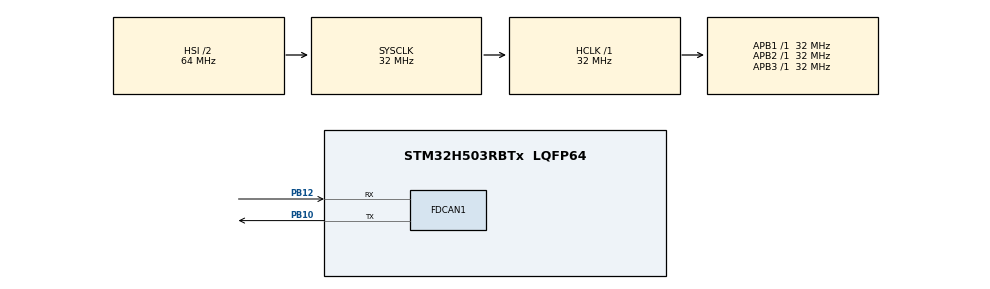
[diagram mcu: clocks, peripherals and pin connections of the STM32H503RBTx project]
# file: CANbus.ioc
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BOOTPATH.BootPathName=LEGACY
BOOTPATH.UserSelectedBootPath=LEGACY
FDCAN1.CalculateBaudRateNominal=500000
FDCAN1.CalculateTimeBitNominal=2000
FDCAN1.CalculateTimeQuantumNominal=200.0
FDCAN1.Mode=FDCAN_MODE_EXTERNAL_LOOPBACK
FDCAN1.NominalPrescaler=10
FDCAN1.NominalTimeSeg1=8
FDCAN1.NominalTimeSeg2=1
Mcu.Family=STM32H5
Mcu.Name=STM32H503RBTx
Mcu.Package=LQFP64
NVIC.FDCAN1_IT0_IRQn=true\:0\:0\:false\:false\:true\:true\:true\:true
NVIC.PriorityGroup=NVIC_PRIORITYGROUP_4
PB10.Mode=FDCAN_Activate
PB10.Signal=FDCAN1_TX
PB12.Mode=FDCAN_Activate
PB12.Signal=FDCAN1_RX
ProjectManager.HeapSize=0x200
ProjectManager.StackSize=0x400
ProjectManager.TargetToolchain=STM32CubeIDE
RCC.ADCFreq_Value=32000000
RCC.AHBFreq_Value=32000000
RCC.APB1Freq_Value=32000000
RCC.APB1TimFreq_Value=32000000
RCC.APB2Freq_Value=32000000
RCC.APB2TimFreq_Value=32000000
RCC.APB3Freq_Value=32000000
RCC.CSI_VALUE=4000000
RCC.CortexFreq_Value=32000000
RCC.EPOD_VALUE=4000000
RCC.FDCANClockSelection=RCC_FDCANCLKSOURCE_PLL1Q
RCC.HCLKFreq_Value=32000000
RCC.HSE_VALUE=25000000
RCC.HSI48_VALUE=48000000
RCC.HSI_VALUE=64000000
RCC.LSE_VALUE=32768
RCC.LSIRC_VALUE=32000
RCC.PLL1Q=4
RCC.PLLFRACN=0
RCC.PLLN=50
RCC.SYSCLKFreq_VALUE=32000000
RCC.USBFreq_Value=48000000
RCC.VCOOutputFreq_Value=200000000
VP_BOOTPATH_VS_BOOTPATH.Mode=BP_Activate
VP_CORTEX_M33_NS_VS_Hclk.Mode=Hclk_Mode
VP_CRC_VS_CRC.Mode=CRC_Activate
VP_ICACHE_VS_ICACHE.Mode=DirectMappedCache
VP_MEMORYMAP_VS_MEMORYMAP.Mode=CurAppReg
VP_PWR_VS_DBSignals.Mode=DisableDeadBatterySignals
VP_PWR_VS_LPOM.Mode=PowerOptimisation
VP_PWR_VS_SECSignals.Mode=Security/Privilege
board=custom

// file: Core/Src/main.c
/* USER CODE BEGIN Header */
/**
  ******************************************************************************
  * @file           : main.c
  * @brief          : Main program body
  ******************************************************************************
  * @attention
  *
  * Copyright (c) 2025 STMicroelectronics.
  * All rights reserved.
  *
  * This software is licensed under terms that can be found in the LICENSE file
  * in the root directory of this software component.
  * If no LICENSE file comes with this software, it is provided AS-IS.
  *
  ******************************************************************************
  */
/* USER CODE END Header */
#include "main.h"

CRC_HandleTypeDef hcrc;

FDCAN_HandleTypeDef hfdcan1;

/* USER CODE BEGIN PV */
FDCAN_TxHeaderTypeDef   TxHeader;
FDCAN_RxHeaderTypeDef   RxHeader;
uint8_t               TxData[8];
uint8_t               RxData[8];
int indx = 0;
/* USER CODE END PV */

void SystemClock_Config(void);
static void MX_GPIO_Init(void);
static void MX_FDCAN1_Init(void);
static void MX_ICACHE_Init(void);
static void MX_CRC_Init(void);

/* USER CODE BEGIN 0 */
void HAL_FDCAN_RxFifo0Callback(FDCAN_HandleTypeDef *hfdcan, uint32_t RxFifo0ITs)
{
	if((RxFifo0ITs & FDCAN_IT_RX_FIFO0_NEW_MESSAGE) != RESET)
	{
		/* Retreive Rx messages from RX FIFO0 */
		if (HAL_FDCAN_GetRxMessage(hfdcan, FDCAN_RX_FIFO0, &RxHeader, RxData) != HAL_OK)
		{
			/* Reception Error */
			Error_Handler();
		}
		if (HAL_FDCAN_ActivateNotification(hfdcan, FDCAN_IT_RX_FIFO0_NEW_MESSAGE, 0) != HAL_OK)
		{
			/* Notification Error */
			Error_Handler();
		}
	}
}
/* USER CODE END 0 */

int main(void)
{

  /* MCU Configuration--------------------------------------------------------*/

  /* Reset of all peripherals, Initializes the Flash interface and the Systick. */
  HAL_Init();

  /* Configure the system clock */
  SystemClock_Config();

  /* Initialize all configured peripherals */
  MX_GPIO_Init();
  MX_FDCAN1_Init();
  MX_ICACHE_Init();
  MX_CRC_Init();
  /* USER CODE BEGIN 2 */
  if(HAL_FDCAN_Start(&hfdcan1)!= HAL_OK)
  {
	Error_Handler();
  }
  if (HAL_FDCAN_ActivateNotification(&hfdcan1, FDCAN_IT_RX_FIFO0_NEW_MESSAGE, 0) != HAL_OK)
  {
	/* Notification Error */
	Error_Handler();
  }

  TxHeader.Identifier = 0x1;
  TxHeader.IdType = FDCAN_STANDARD_ID;
  TxHeader.TxFrameType = FDCAN_DATA_FRAME;
  TxHeader.DataLength = FDCAN_DLC_BYTES_8;
  TxHeader.ErrorStateIndicator = FDCAN_ESI_ACTIVE;
  TxHeader.BitRateSwitch = FDCAN_BRS_OFF;
  TxHeader.FDFormat = FDCAN_FD_CAN;
  TxHeader.TxEventFifoControl = FDCAN_NO_TX_EVENTS;
  TxHeader.MessageMarker = 0;

  for (int i=0; i<8; i++)
  {
	  TxData[i] = i;
  }

  if (HAL_FDCAN_AddMessageToTxFifoQ(&hfdcan1, &TxHeader, TxData)!= HAL_OK)
  {
	  Error_Handler();
  }
  /* USER CODE END 2 */

  /* Infinite loop */
  while (1)
  {

  }
}

void SystemClock_Config(void)
{
  RCC_OscInitTypeDef RCC_OscInitStruct = {0};
  RCC_ClkInitTypeDef RCC_ClkInitStruct = {0};

  /** Configure the main internal regulator output voltage
  */
  __HAL_PWR_VOLTAGESCALING_CONFIG(PWR_REGULATOR_VOLTAGE_SCALE3);

  while(!__HAL_PWR_GET_FLAG(PWR_FLAG_VOSRDY)) {}

  /** Initializes the RCC Oscillators according to the specified parameters
  * in the RCC_OscInitTypeDef structure.
  */
  RCC_OscInitStruct.OscillatorType = RCC_OSCILLATORTYPE_HSI|RCC_OSCILLATORTYPE_CSI;
  RCC_OscInitStruct.HSIState = RCC_HSI_ON;
  RCC_OscInitStruct.HSIDiv = RCC_HSI_DIV2;
  RCC_OscInitStruct.HSICalibrationValue = RCC_HSICALIBRATION_DEFAULT;
  RCC_OscInitStruct.CSIState = RCC_CSI_ON;
  RCC_OscInitStruct.CSICalibrationValue = RCC_CSICALIBRATION_DEFAULT;
  RCC_OscInitStruct.PLL.PLLState = RCC_PLL_ON;
  RCC_OscInitStruct.PLL.PLLSource = RCC_PLL1_SOURCE_CSI;
  RCC_OscInitStruct.PLL.PLLM = 1;
  RCC_OscInitStruct.PLL.PLLN = 50;
  RCC_OscInitStruct.PLL.PLLP = 2;
  RCC_OscInitStruct.PLL.PLLQ = 4;
  RCC_OscInitStruct.PLL.PLLR = 2;
  RCC_OscInitStruct.PLL.PLLRGE = RCC_PLL1_VCIRANGE_2;
  RCC_OscInitStruct.PLL.PLLVCOSEL = RCC_PLL1_VCORANGE_WIDE;
  RCC_OscInitStruct.PLL.PLLFRACN = 0;
  if (HAL_RCC_OscConfig(&RCC_OscInitStruct) != HAL_OK)
  {
    Error_Handler();
  }

  /** Initializes the CPU, AHB and APB buses clocks
  */
  RCC_ClkInitStruct.ClockType = RCC_CLOCKTYPE_HCLK|RCC_CLOCKTYPE_SYSCLK
                              |RCC_CLOCKTYPE_PCLK1|RCC_CLOCKTYPE_PCLK2
                              |RCC_CLOCKTYPE_PCLK3;
  RCC_ClkInitStruct.SYSCLKSource = RCC_SYSCLKSOURCE_HSI;
  RCC_ClkInitStruct.AHBCLKDivider = RCC_SYSCLK_DIV1;
  RCC_ClkInitStruct.APB1CLKDivider = RCC_HCLK_DIV1;
  RCC_ClkInitStruct.APB2CLKDivider = RCC_HCLK_DIV1;
  RCC_ClkInitStruct.APB3CLKDivider = RCC_HCLK_DIV1;

  if (HAL_RCC_ClockConfig(&RCC_ClkInitStruct, FLASH_LATENCY_1) != HAL_OK)
  {
    Error_Handler();
  }
}

static void MX_CRC_Init(void)
{

  hcrc.Instance = CRC;
  hcrc.Init.DefaultPolynomialUse = DEFAULT_POLYNOMIAL_ENABLE;
  hcrc.Init.DefaultInitValueUse = DEFAULT_INIT_VALUE_ENABLE;
  hcrc.Init.InputDataInversionMode = CRC_INPUTDATA_INVERSION_NONE;
  hcrc.Init.OutputDataInversionMode = CRC_OUTPUTDATA_INVERSION_DISABLE;
  hcrc.InputDataFormat = CRC_INPUTDATA_FORMAT_BYTES;
  if (HAL_CRC_Init(&hcrc) != HAL_OK)
  {
    Error_Handler();
  }

}

static void MX_FDCAN1_Init(void)
{

  hfdcan1.Instance = FDCAN1;
  hfdcan1.Init.ClockDivider = FDCAN_CLOCK_DIV1;
  hfdcan1.Init.FrameFormat = FDCAN_FRAME_CLASSIC;
  hfdcan1.Init.Mode = FDCAN_MODE_EXTERNAL_LOOPBACK;
  hfdcan1.Init.AutoRetransmission = DISABLE;
  hfdcan1.Init.TransmitPause = DISABLE;
  hfdcan1.Init.ProtocolException = DISABLE;
  hfdcan1.Init.NominalPrescaler = 10;
  hfdcan1.Init.NominalSyncJumpWidth = 1;
  hfdcan1.Init.NominalTimeSeg1 = 8;
  hfdcan1.Init.NominalTimeSeg2 = 1;
  hfdcan1.Init.DataPrescaler = 1;
  hfdcan1.Init.DataSyncJumpWidth = 1;
  hfdcan1.Init.DataTimeSeg1 = 1;
  hfdcan1.Init.DataTimeSeg2 = 1;
  hfdcan1.Init.StdFiltersNbr = 0;
  hfdcan1.Init.ExtFiltersNbr = 0;
  hfdcan1.Init.TxFifoQueueMode = FDCAN_TX_FIFO_OPERATION;
  if (HAL_FDCAN_Init(&hfdcan1) != HAL_OK)
  {
    Error_Handler();
  }

}

static void MX_ICACHE_Init(void)
{

  /** Enable instruction cache in 1-way (direct mapped cache)
  */
  if (HAL_ICACHE_ConfigAssociativityMode(ICACHE_1WAY) != HAL_OK)
  {
    Error_Handler();
  }
  if (HAL_ICACHE_Enable() != HAL_OK)
  {
    Error_Handler();
  }

}

static void MX_GPIO_Init(void)
{

  /* GPIO Ports Clock Enable */
  __HAL_RCC_GPIOB_CLK_ENABLE();

}

void Error_Handler(void)
{
  __disable_irq();
  while (1)
  {
  }
}
